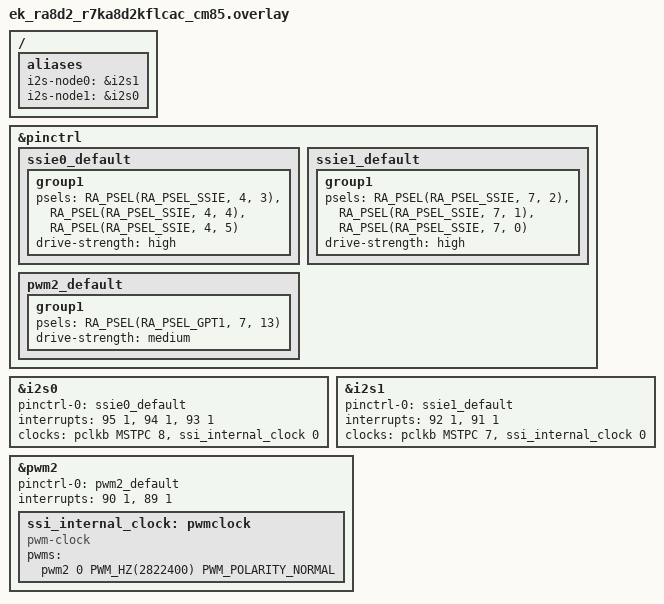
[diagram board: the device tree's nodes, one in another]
/*
 * Copyright (c) 2025 Renesas Electronics Corporation
 *
 * SPDX-License-Identifier: Apache-2.0
 */

#include <zephyr/dt-bindings/pwm/pwm.h>

/ {
	aliases {
		i2s-node0 = &i2s1;
		i2s-node1 = &i2s0;
	};
};

&pinctrl {
	ssie0_default: ssie0_default {
		group1 {
			/* SSI_BCK SSI_LRCK SSI_TX */
			psels = <RA_PSEL(RA_PSEL_SSIE, 4, 3)>,
				<RA_PSEL(RA_PSEL_SSIE, 4, 4)>,
				<RA_PSEL(RA_PSEL_SSIE, 4, 5)>;
			drive-strength = "high";
		};
	};

	ssie1_default: ssie1_default {
		group1 {
			/* SSI_BCK SSI_LRCK SSI_DATA */
			psels = <RA_PSEL(RA_PSEL_SSIE, 7, 2)>,
				<RA_PSEL(RA_PSEL_SSIE, 7, 1)>,
				<RA_PSEL(RA_PSEL_SSIE, 7, 0)>;
			drive-strength = "high";
		};
	};

	pwm2_default: pwm2_default {
		group1 {
			/* GTIOC2A */
			psels = <RA_PSEL(RA_PSEL_GPT1, 7, 13)>;
			drive-strength = "medium";
		};
	};
};

&i2s0 {
	pinctrl-0 = <&ssie0_default>;
	pinctrl-names = "default";
	interrupts = <95 1>, <94 1>, <93 1>;
	interrupt-names = "ssi_txi", "ssi_rxi", "ssi_if";
	status = "okay";
	clocks = <&pclkb MSTPC 8>, <&ssi_internal_clock 0>;
	clock-names = "pclk", "audio-clock";
};

&i2s1 {
	pinctrl-0 = <&ssie1_default>;
	pinctrl-names = "default";
	interrupts = <92 1>, <91 1>;
	interrupt-names = "ssi_rt", "ssi_if";
	status = "okay";
	clocks = <&pclkb MSTPC 7>, <&ssi_internal_clock 0>;
	clock-names = "pclk", "audio-clock";
};

&pwm2 {
	pinctrl-0 = <&pwm2_default>;
	pinctrl-names = "default";
	interrupts = <90 1>, <89 1>;
	interrupt-names = "gtioca", "overflow";
	status = "okay";

	ssi_internal_clock: pwmclock {
		status = "okay";
		compatible = "pwm-clock";
		#clock-cells = <1>;
		pwms = <&pwm2 0 PWM_HZ(2822400) PWM_POLARITY_NORMAL>;
	};
};
